# YTM32B1ME1 register map
Vendor: YTMicro; File version: 1.0
CPU: CM33 r0p4, little endian, MPU, FPU, 2 interrupt priority bits
Registers are 32-bit, read-write, reset 0x0 unless marked. A register's access mark holds for its fields unless they carry their own. Offsets are from the block's base; [hi:lo] are bit positions; {n}, {i} and the like mark numbered series; 'fields as' and 'values as' point back to an identical list; <NAME> marks a mode.

## EFM — Embedded Flash Module
Base 0x40040000; register names take the prefix EFM_
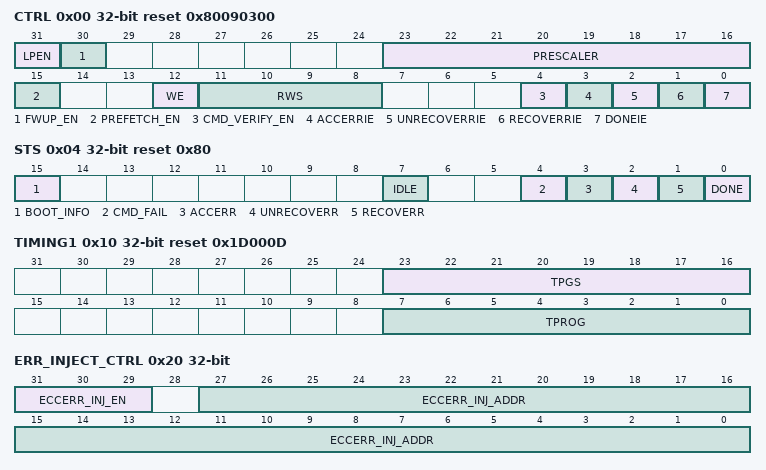
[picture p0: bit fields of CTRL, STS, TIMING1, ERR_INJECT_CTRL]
0x00 CTRL reset 0x80090300
  [31] LPEN — This LPEN bit determines whether the Flash array will enter low power mode when the MCU send a sleep request. ewline This register bit is reset by System Reset.
    0=Flash will keep active when the MCU send a sleep request; 1=Flash will enter low power mode when the MCU send a sleep request
  [30] FWUP_EN — This FWUP_EN bit determines whether enables fast wake-up of the Flash array. Power consumption of fast wake-up is bigger than normal wake-up. ewline This register bit is reset by System Reset.
    0=Flash wake-up time from Deep Standby mode is 20us; 1=Flash wake-up time from Deep Standby mode is 10us
  [23:16] PRESCALER — These PRESCALER bits are used for EFM operation time control. ewline Please use the following equation to calculate the PRESCALER value: ewline PRESCALER = Slow bus clock frequency / 2 ewline Round up if not divisible. ewline The unit of Slow bus clock frequency is Mhz. ewline For example, if Slow bus clock frequency is 40Mhz, PRESCALER value should be 20. ewline Please re-configure PRESCALER once the frequency is changed. ewline This register bit is reset by System Reset.
  [15] PREFETCH_EN — This PREFETCH_EN bit is used to enable Flash prefetch read function. ewline EFM will prefetch the data from next Flash address (current Flash address + 1) when corresponding Flash array is free. Then if next read access address is equal to prefetch address, Flash data will be delivered without waiting for Flash access time. ewline Only PFlash supports pre-fetch function, bus read of NVR array will ignore this register bit. ewline This register bit is reset by System Reset.
    0=Disable pre-fetch function; 1=Enable pre-fetch function
  [12] WE — This WE bit determines whether Flash is writable. Write Flash when WE is 0 causes bus error and STS[CI_WEERR] flag is set at the same time. ewline This register bit is reset by System Reset.
    0=Disable Flash write; 1=Enable Flash write
  [11:8] RWS
    0=In-valid value for RWS configuration; 1=Valid value for fast bus clk <= 60MHz; 2=Valid value for 60MHz < fast bus clk <= 90MHz; 3=Valid value for 90MHz < fast bus clk <= 120MHz; 4=In-valid value for RWS configuration
  [4] CMD_VERIFY_EN — This CMD_VERIFY_EN bit determines whether to do verify read after erase or program operation during executing a command. ewline - After each program cycle, if CMD_VERIFY_EN=1, EFM should read the programmed address and compare the read data to program data, if not equal, set STS[CMD_FAIL] flag to 1. ewline - After each erase cycle, if CMD_VERIFY_EN=1, EFM should read the erased addresses and compare read data with FF, if read data are not all FF, set STS[CMD_FAIL] flag to 1. ewline This register bit is reset by System Reset.
    0=Disable verify read after erase or program cycle; 1=Enable verify read after erase or program cycle
  [3] ACCERRIE — This ACCERRIE bit determines whether the interrupt will be generated when STS[ACCERR] flag is asserted. ewline This register bit is reset by System Reset.
    0=Don't generate interrupt when STS[ACCERR] flag is asserted; 1=Generate interrupt when STS[ACCERR] flag is asserted
  [2] UNRECOVERRIE — This UNRECOVERRIE bit determines whether the interrupt will be generated when STS[UNRECOVERR] flag is asserted. ewline This register bit is reset by System Reset.
    0=Don't generate interrupt when STS[UNRECOVERR] flag is asserted; 1=Generate interrupt when STS[UNRECOVERR] flag is asserted
  [1] RECOVERRIE — This RECOVERRIE bit determines whether the interrupt will be generated when STS[RECOVERR] flag is asserted. ewline This register bit is reset by System Reset.
    0=Don't generate interrupt when STS[RECOVER] flag is asserted; 1=Generate interrupt when STS[RECOVERR] flag is asserted
  [0] DONEIE — This DONEIE bit determines whether the interrupt will be generated when DONE flag is asserted. ewline This register bit is reset by System Reset.
    0=Don't generate interrupt when STS[DONE] flag is asserted; 1=Generate interrupt when STS[DONE] flag is asserted
0x04 STS reset 0x80
  [15] BOOT_INFO ro — This BOOT_INFO bit indicates whether address remap is enabled. ewline This register bit is reset by System Reset.
    0=Address remap is disabled; 1=Address remap is enabled. Refer to \hyperref[boot-swap-operation]{Boot-Swap Operation} for more details.
  [7] IDLE ro — This IDLE bit indicates whether EFM is busy executing a command. ewline This register bit is reset by System Reset.
    0=EFM is execting a command; 1=EFM is idle
  [4] CMD_FAIL — This CMD_FAIL bit indicates whether the current command is failed. ewline Command failure includes below scenarios: ewline - Read check before a program cycle failed if data and ECC bits are not all FF. ewline - Verify check after a erase cycle failed if data and ECC bits are not cleared to all FF. ewline - Verify check after a program cycle failed if program data not equal to read data. ewline This register bit is reset by System Reset.
  [3] ACCERR — This ACCERR bit indicates whether an access error is detected. This flag is set after write CMD. When an access error occurred, the command is not launched. ewline Access error scenarios refer to \hyperref[flash-abnormal-operation]{Flash Abnormal Operation}. ewline This register bit is reset by System Reset.
    0=Access error is not detected; 1=Access error is detected
  [2] UNRECOVERR — This UNRECOVERR bit indicates whether a 2-bit ECC error is detected during Flash read. ewline This register bit is reset by Power-on Reset.
    0=No un-recovery ECC error is detected; 1=2-bit ECC error is detected
  [1] RECOVERR — This RECOVERR bit indicates whether a 1-bit ECC error is detected during Flash read. ewline This register bit is reset by Power-on Reset.
    0=No recovery ECC error is detected; 1=1-bit ECC error is detected
  [0] DONE — This DONE bit indicates whether the current command is completed. ewline This register bit is reset by System Reset.
    0=Current command is in progress; 1=Current command is completed
0x08 CMD
  [7:0] CMD — These CMD bits determine which commands are available. Write valid command code to CMD to launch a command. Refer to table \hyperref[efm-commands]{EFM commands} for command code. ewline This register bit is reset by System Reset.
0x0C CMD_PROT
  [31:0] CMD_PROT — These CMD_PROT is used to disable commands. ewline Once bit CMD_PROTn is set HIGH, its corresponding command is disabled. Refer to \hyperref[efm-commands]{EFM commands} table for the map between commands and CMD_PROT bits ewline This register bit is reset by System Reset.
0x10 TIMING1 reset 0x1D000D
  [23:16] TPGS — These TPGS bits indicate the setup time of program. ewline The valid setup time of program is from 70us to 90us. The time unit of TPGS is 0.5us. ewline So that the TPGS value range is 140 to 180. ewline For example, if TPGS value is 140, the Flash array program setup time is 140*0.5us=70us.
  [7:0] TPROG — These TPROG bits indicate the program pulse time. ewline The valid program pulse time is from 7us to 8.5us. The time unit of TPROG is 0.5us. So that the TPROG value range is 14 to 17. ewline For example, if TPROG value is 10, the Flash array program pulse time is 10*0.5us=5us. ewline This register bit is reset by System Reset.
0x14 TIMING2 reset 0xFA2
  [15:0] TERASE — These TERASE bits indicate the erase pulse times. ewline For Multi-Pulse Sector Erase, the valid erase pulse time is from 400us to 510us. ewline For Sector Erase, the valid erase pulse time is from 2ms to 3ms. ewline For Block Erase, the valid erase pulse time is from 30ms to 40ms. ewline The time unit of TERASE is 0.5us. For example, if TERASE value is 4000, the Flash array sector erase pulse time is 4000*0.5us=2ms. ewline This register bit is reset by System Reset. ote{Please set TERASE register to valid value before send ERASE_SECTOR or ERASE_BLOCK command.}
0x20 ERR_INJECT_CTRL
  [31:29] ECCERR_INJ_EN — Set this ECCERR_INJ_EN bits while cause 1-bit/ 2-bit ECC error for Flash reading. ewline This register bit is reset by System Reset.
    0=000b (Disable ECC error inject .); 1=001b (Inject 1-bit ECC error for target address.); 2=010b (Inject 2-bit ECC error for target address.); 5=101b (Inject 1-bit ECC error for any address.); 6=110b (Inject 2-bit ECC error for any address.)
  [27:0] ECCERR_INJ_ADDR — Please set target inject SOC address of PFlash before enable ecc error injection. ewline Once enable the ecc error injection, read target address of flash will generate corresponding ecc error. ewline This register bit is reset by System Reset.
0x24 ADDR_PROT0 reset 0xFFFFFFFF
  [31:0] ADDR_PROT — The address area of each PFlash is divided into 32 regions. Each region is protected by one bit of ADDR_PROT. The address area of each region is 16KB. ewline If any bit is set to 0, its corresponding region is under protection (read only). ewline EFM hardware initialization flow (STS[IDLE]=0) will load ADDR_PROT registers with initial values from CUS_NVR array if the CUS_NVR has programmed with initial ADDR_PROT values and tag. ewline After EFM hardware initialization done (STS[IDLE]=1), software can write 0 to value 1 bit of ADDR_PROT, but can not write 1 to value 0 bit. ewline This register bit is reset by System Reset.
0x28 ADDR_PROT1 reset 0xFFFFFFFF
  fields as ADDR_PROT0
0x30 ECCERR_ADDR reset 0xFFFFFFFF
  [31:0] ERR_FLASH_ADDR ro — These bits records the first detected ECC error address. Followed ECC error addresses are not recorded. ewline This register bit is reset by Power-on Reset. ewline When detecting an ECC error, hardware will set ECC error flag (RECOVERR or UNRECOVERR) and record information about error Flash address and error array. Read ECCERR_ADDR can get SOC address of the recorded ECC error. ewline ECCERR_ADDR is cleared by writing 1 to the corresponding error flag. For example, if ECCERR_ADDR records UNRECOVERR address information, only write 1 to UNRECOVERR can clear ECCERR_ADDR, writing 1 to RECOVERR can not clear ECCERR_ADDR. ewline ECCERR_ADDR is aligned to 8Byte because a FLash read get a 64-bit page data. When recorded an ECC error address in ECCERR_ADDR, any bus read of Flash address located in ECCERR_ADDR~(ECCERR_ADDR+0x7) will get ECC error too. ewline
0x34 ECCERR_CNT
  [15:0] ECCERR_CNT ro — These ECCERR_CNT bits record 1-bit and 2-bit ECC errors. ewline This register bit is reset by Power-on Reset.
0x200 CMD_UNLOCK wo
  [31:0] CMD_UNLOCK_KEY — Please write 0xfd9573f5 before launching a command
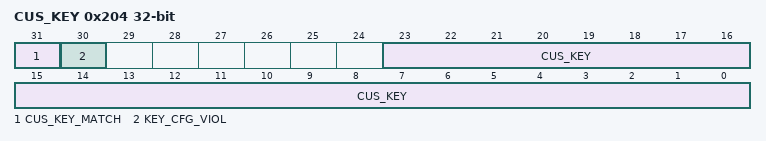
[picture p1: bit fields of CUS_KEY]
0x204 CUS_KEY
  [31] CUS_KEY_MATCH ro — This CUS_KEY_MATCH bit indicates whether Customer Key is matched. ewline Write correct CUS_KEY value will set this flag ewline Write any incorrect value will clear this flag. ewline This register bit is reset by System Reset.
    0=Customer Key is not matched; 1=Customer Key is matched
  [30] KEY_CFG_VIOL ro — This KEY_CFG_VIOL bit indicates whether CUS_KEY/FAC_KEY is mis-matched. ewline Write CUS_KEY/FAC_KEY with incorrect value will set this flag. ewline Once this flag is set, key configuration is blocked, even if user sets correct key value, corresponding key match flag will not be set. ewline This register bit is reset by Power-on Reset.
    0=Set Cus_Key or Fac_Key is matched; 1=Set Cus_Key or Fac_Key is not matched
  [23:0] CUS_KEY wo — Following are Customer Key protected operations, please write CUS_KEY with correct value before doing these operations: ewline - Read or erase or program CUS_NVR ewline - Erase HCU_NVR array if it is exist ewline Default Customer Key value is 0x4DFF32 and the Customer Key can be re-defined by programming the first address of CUS_NVR, it will be effective after EFM is reset.
0x300 CTRL_OVRD ro
  [3] DBG_DISABLE — This bit determines whether the Software Debugger is disabled. ewline This register bit is reset by System Reset.
    0=Software Debugger is enabled; 1=Software Debugger is disabled
